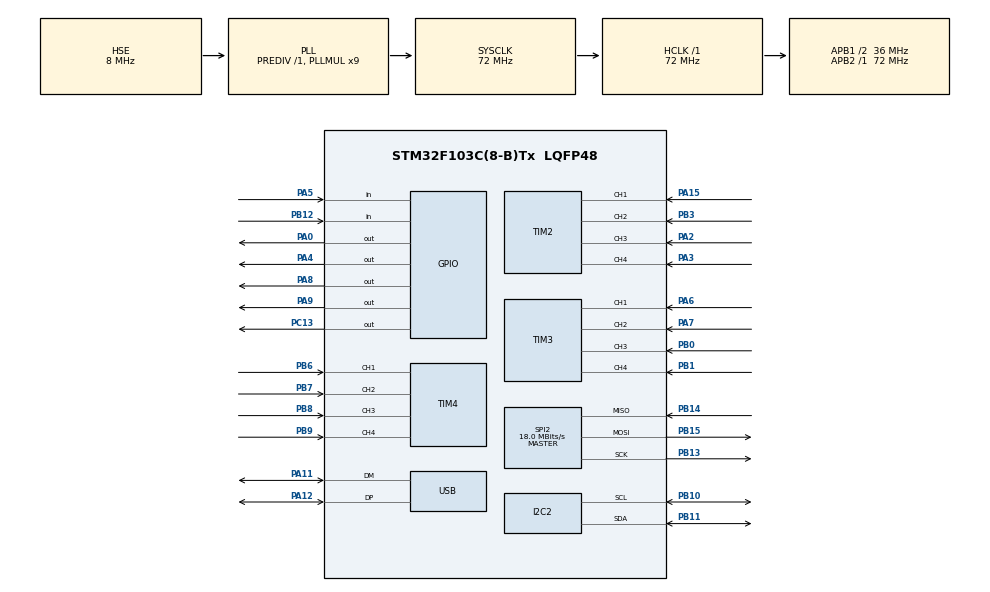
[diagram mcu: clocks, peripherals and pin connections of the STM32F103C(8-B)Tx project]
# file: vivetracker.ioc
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Mcu.Family=STM32F1
Mcu.Name=STM32F103C(8-B)Tx
Mcu.Package=LQFP48
NVIC.PriorityGroup=NVIC_PRIORITYGROUP_4
PA0-WKUP.Signal=GPIO_Output
PA11.Mode=Device
PA11.Signal=USB_DM
PA12.Mode=Device
PA12.Signal=USB_DP
PA13.Mode=Serial_Wire
PA13.Signal=SYS_JTMS-SWDIO
PA14.Mode=Serial_Wire
PA14.Signal=SYS_JTCK-SWCLK
PA15.Signal=S_TIM2_CH1_ETR
PA2.Signal=S_TIM2_CH3
PA3.Signal=S_TIM2_CH4
PA4.Signal=GPIO_Output
PA5.Signal=GPIO_Input
PA6.Signal=S_TIM3_CH1
PA7.Signal=S_TIM3_CH2
PA8.Signal=GPIO_Output
PA9.Signal=GPIO_Output
PB0.Signal=S_TIM3_CH3
PB1.Signal=S_TIM3_CH4
PB10.Mode=I2C
PB10.Signal=I2C2_SCL
PB11.Mode=I2C
PB11.Signal=I2C2_SDA
PB12.Signal=GPIO_Input
PB13.Mode=Full_Duplex_Master
PB13.Signal=SPI2_SCK
PB14.Mode=Full_Duplex_Master
PB14.Signal=SPI2_MISO
PB15.Mode=Full_Duplex_Master
PB15.Signal=SPI2_MOSI
PB3.Signal=S_TIM2_CH2
PB6.Signal=S_TIM4_CH1
PB7.Signal=S_TIM4_CH2
PB8.Signal=S_TIM4_CH3
PB9.Signal=S_TIM4_CH4
PC13-TAMPER-RTC.Signal=GPIO_Output
PD0-OSC_IN.Mode=HSE-External-Oscillator
PD0-OSC_IN.Signal=RCC_OSC_IN
PD1-OSC_OUT.Mode=HSE-External-Oscillator
PD1-OSC_OUT.Signal=RCC_OSC_OUT
ProjectManager.HeapSize=0x200
ProjectManager.StackSize=0x400
ProjectManager.TargetToolchain=Makefile
RCC.AHBFreq_Value=72000000
RCC.APB1CLKDivider=RCC_HCLK_DIV2
RCC.APB1Freq_Value=36000000
RCC.APB1TimFreq_Value=72000000
RCC.APB2Freq_Value=72000000
RCC.APB2TimFreq_Value=72000000
RCC.HCLKFreq_Value=72000000
RCC.PLLMUL=RCC_PLL_MUL9
RCC.SYSCLKFreq_VALUE=72000000
RCC.SYSCLKSource=RCC_SYSCLKSOURCE_PLLCLK
RCC.USBFreq_Value=48000000
RCC.USBPrescaler=RCC_USBCLKSOURCE_PLL_DIV1_5
SH.S_TIM2_CH1_ETR.0=TIM2_CH1,Input_Capture1_from_TI1
SH.S_TIM2_CH2.0=TIM2_CH2,Input_Capture2_from_TI2
SH.S_TIM2_CH3.0=TIM2_CH3,Input_Capture3_from_TI3
SH.S_TIM2_CH4.0=TIM2_CH4,Input_Capture4_from_TI4
SH.S_TIM3_CH1.0=TIM3_CH1,Input_Capture1_from_TI1
SH.S_TIM3_CH2.0=TIM3_CH2,Input_Capture2_from_TI2
SH.S_TIM3_CH3.0=TIM3_CH3,Input_Capture3_from_TI3
SH.S_TIM3_CH4.0=TIM3_CH4,Input_Capture4_from_TI4
SH.S_TIM4_CH1.0=TIM4_CH1,Input_Capture1_from_TI1
SH.S_TIM4_CH2.0=TIM4_CH2,Input_Capture2_from_TI2
SH.S_TIM4_CH3.0=TIM4_CH3,Input_Capture3_from_TI3
SH.S_TIM4_CH4.0=TIM4_CH4,Input_Capture4_from_TI4
SPI2.CalculateBaudRate=18.0 MBits/s
SPI2.Direction=SPI_DIRECTION_2LINES
SPI2.Mode=SPI_MODE_MASTER
SPI2.VirtualType=VM_MASTER
TIM1.Channel-Output\ Compare1\ No\ Output=TIM_CHANNEL_1
TIM2.Channel-Input_Capture1_from_TI1=TIM_CHANNEL_1
TIM2.Channel-Input_Capture2_from_TI2=TIM_CHANNEL_2
TIM2.Channel-Input_Capture3_from_TI3=TIM_CHANNEL_3
TIM2.Channel-Input_Capture4_from_TI4=TIM_CHANNEL_4
TIM3.Channel-Input_Capture1_from_TI1=TIM_CHANNEL_1
TIM3.Channel-Input_Capture2_from_TI2=TIM_CHANNEL_2
TIM3.Channel-Input_Capture3_from_TI3=TIM_CHANNEL_3
TIM3.Channel-Input_Capture4_from_TI4=TIM_CHANNEL_4
TIM4.Channel-Input_Capture1_from_TI1=TIM_CHANNEL_1
TIM4.Channel-Input_Capture2_from_TI2=TIM_CHANNEL_2
TIM4.Channel-Input_Capture3_from_TI3=TIM_CHANNEL_3
TIM4.Channel-Input_Capture4_from_TI4=TIM_CHANNEL_4
VP_TIM1_VS_ClockSourceINT.Mode=Internal
VP_TIM1_VS_no_output1.Mode=Output Compare1 No Output
VP_TIM2_VS_ClockSourceINT.Mode=Internal
VP_TIM3_VS_ClockSourceINT.Mode=Internal
VP_TIM4_VS_ClockSourceINT.Mode=Internal
board=vivetracker

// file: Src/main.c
/**
  ******************************************************************************
  * @file           : main.c
  * @brief          : Main program body
  ******************************************************************************
  ** This notice applies to any and all portions of this file
  * that are not between comment pairs USER CODE BEGIN and
  * USER CODE END. Other portions of this file, whether
  * inserted by the user or by software development tools
  * are owned by their respective copyright owners.
  *
  * COPYRIGHT(c) 2018 STMicroelectronics
  *
  * Redistribution and use in source and binary forms, with or without modification,
  * are permitted provided that the following conditions are met:
  *   1. Redistributions of source code must retain the above copyright notice,
  *      this list of conditions and the following disclaimer.
  *   2. Redistributions in binary form must reproduce the above copyright notice,
  *      this list of conditions and the following disclaimer in the documentation
  *      and/or other materials provided with the distribution.
  *   3. Neither the name of STMicroelectronics nor the names of its contributors
  *      may be used to endorse or promote products derived from this software
  *      without specific prior written permission.
  *
  * THIS SOFTWARE IS PROVIDED BY THE COPYRIGHT HOLDERS AND CONTRIBUTORS "AS IS"
  * AND ANY EXPRESS OR IMPLIED WARRANTIES, INCLUDING, BUT NOT LIMITED TO, THE
  * IMPLIED WARRANTIES OF MERCHANTABILITY AND FITNESS FOR A PARTICULAR PURPOSE ARE
  * DISCLAIMED. IN NO EVENT SHALL THE COPYRIGHT HOLDER OR CONTRIBUTORS BE LIABLE
  * FOR ANY DIRECT, INDIRECT, INCIDENTAL, SPECIAL, EXEMPLARY, OR CONSEQUENTIAL
  * DAMAGES (INCLUDING, BUT NOT LIMITED TO, PROCUREMENT OF SUBSTITUTE GOODS OR
  * SERVICES; LOSS OF USE, DATA, OR PROFITS; OR BUSINESS INTERRUPTION) HOWEVER
  * CAUSED AND ON ANY THEORY OF LIABILITY, WHETHER IN CONTRACT, STRICT LIABILITY,
  * OR TORT (INCLUDING NEGLIGENCE OR OTHERWISE) ARISING IN ANY WAY OUT OF THE USE
  * OF THIS SOFTWARE, EVEN IF ADVISED OF THE POSSIBILITY OF SUCH DAMAGE.
  *
  ******************************************************************************
  */
#include "main.h"
#include "stm32f1xx_hal.h"
#include "i2c.h"
#include "spi.h"
#include "tim.h"
#include "usb.h"
#include "gpio.h"

/* USER CODE BEGIN Includes */
#include "vivetracker_c_api.h"
/* USER CODE END Includes */

/* USER CODE BEGIN PV */
/* Private variables ---------------------------------------------------------*/

/* USER CODE END PV */

void SystemClock_Config(void);

/* USER CODE BEGIN PFP */
/* Private function prototypes -----------------------------------------------*/

/* USER CODE END PFP */

int main(void)
{

  /* MCU Configuration----------------------------------------------------------*/

  /* Reset of all peripherals, Initializes the Flash interface and the Systick. */
  HAL_Init();

  /* Configure the system clock */
  SystemClock_Config();

  /* Initialize all configured peripherals */
  MX_GPIO_Init();
  MX_TIM4_Init();
  MX_TIM2_Init();
  MX_TIM1_Init();
  MX_TIM3_Init();
  MX_I2C2_Init();
  MX_SPI2_Init();
  MX_USB_PCD_Init();

  /* Infinite loop */
  /* USER CODE BEGIN WHILE */
  vivetracker_loop();
  /* USER CODE END WHILE */

}

void SystemClock_Config(void)
{

  RCC_OscInitTypeDef RCC_OscInitStruct;
  RCC_ClkInitTypeDef RCC_ClkInitStruct;
  RCC_PeriphCLKInitTypeDef PeriphClkInit;

    /**Initializes the CPU, AHB and APB busses clocks
    */
  RCC_OscInitStruct.OscillatorType = RCC_OSCILLATORTYPE_HSE;
  RCC_OscInitStruct.HSEState = RCC_HSE_ON;
  RCC_OscInitStruct.HSEPredivValue = RCC_HSE_PREDIV_DIV1;
  RCC_OscInitStruct.HSIState = RCC_HSI_ON;
  RCC_OscInitStruct.PLL.PLLState = RCC_PLL_ON;
  RCC_OscInitStruct.PLL.PLLSource = RCC_PLLSOURCE_HSE;
  RCC_OscInitStruct.PLL.PLLMUL = RCC_PLL_MUL9;
  if (HAL_RCC_OscConfig(&RCC_OscInitStruct) != HAL_OK)
  {
    _Error_Handler(__FILE__, __LINE__);
  }

    /**Initializes the CPU, AHB and APB busses clocks
    */
  RCC_ClkInitStruct.ClockType = RCC_CLOCKTYPE_HCLK|RCC_CLOCKTYPE_SYSCLK
                              |RCC_CLOCKTYPE_PCLK1|RCC_CLOCKTYPE_PCLK2;
  RCC_ClkInitStruct.SYSCLKSource = RCC_SYSCLKSOURCE_PLLCLK;
  RCC_ClkInitStruct.AHBCLKDivider = RCC_SYSCLK_DIV1;
  RCC_ClkInitStruct.APB1CLKDivider = RCC_HCLK_DIV2;
  RCC_ClkInitStruct.APB2CLKDivider = RCC_HCLK_DIV1;

  if (HAL_RCC_ClockConfig(&RCC_ClkInitStruct, FLASH_LATENCY_2) != HAL_OK)
  {
    _Error_Handler(__FILE__, __LINE__);
  }

  PeriphClkInit.PeriphClockSelection = RCC_PERIPHCLK_USB;
  PeriphClkInit.UsbClockSelection = RCC_USBCLKSOURCE_PLL_DIV1_5;
  if (HAL_RCCEx_PeriphCLKConfig(&PeriphClkInit) != HAL_OK)
  {
    _Error_Handler(__FILE__, __LINE__);
  }

    /**Configure the Systick interrupt time
    */
  HAL_SYSTICK_Config(HAL_RCC_GetHCLKFreq()/1000);

    /**Configure the Systick
    */
  HAL_SYSTICK_CLKSourceConfig(SYSTICK_CLKSOURCE_HCLK);

  /* SysTick_IRQn interrupt configuration */
  HAL_NVIC_SetPriority(SysTick_IRQn, 0, 0);
}

void _Error_Handler(char *file, int line)
{
  while(1)
  {
  }
}

/************************ (C) COPYRIGHT STMicroelectronics *****END OF FILE****/
